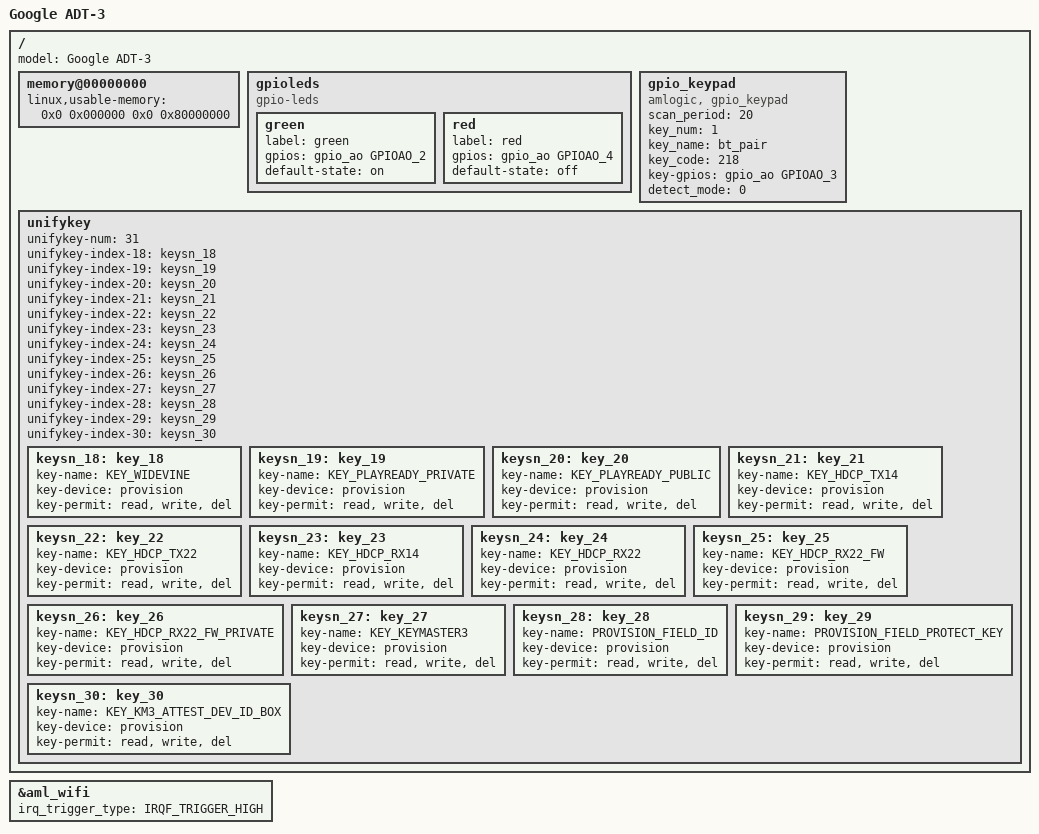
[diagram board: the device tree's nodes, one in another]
// SPDX-License-Identifier: (GPL-2.0+ OR MIT)
/*
 * Google ADT-3 (deadpool), Amlogic S905Y2 (G12A).
 *
 * Shared board description is in g12a_s905y2_common.dtsi.
 */

/dts-v1/;

#include "g12a_s905y2_common.dtsi"

/ {
	model = "Google ADT-3";

	memory@00000000 {
		device_type = "memory";
		linux,usable-memory = <0x0 0x000000 0x0 0x80000000>;
	};

	gpioleds {
		compatible = "gpio-leds";
		status = "okay";

		green {
			label = "green";
			gpios = <&gpio_ao GPIOAO_2 GPIO_ACTIVE_HIGH>;
			default-state = "on";
		};

		red {
			label = "red";
			gpios = <&gpio_ao GPIOAO_4 GPIO_ACTIVE_HIGH>;
			default-state = "off";
		};
	};

	gpio_keypad {
		compatible = "amlogic, gpio_keypad";
		status = "okay";
		scan_period = <20>;
		key_num = <1>;
		key_name = "bt_pair";
		key_code = <218>;
		key-gpios = <&gpio_ao GPIOAO_3 GPIO_ACTIVE_HIGH>;
		detect_mode = <0>;	/* 0:polling, 1:irq */
	};

	/*
	 * Keys 18-30 are the provision-backed DRM, HDCP and keymaster entries.
	 * They are reachable only through a TEE.
	 */
	unifykey {
		unifykey-num = <31>;

		unifykey-index-18= <&keysn_18>;
		unifykey-index-19= <&keysn_19>;
		unifykey-index-20= <&keysn_20>;
		unifykey-index-21= <&keysn_21>;
		unifykey-index-22= <&keysn_22>;
		unifykey-index-23= <&keysn_23>;
		unifykey-index-24= <&keysn_24>;
		unifykey-index-25= <&keysn_25>;
		unifykey-index-26= <&keysn_26>;
		unifykey-index-27= <&keysn_27>;
		unifykey-index-28= <&keysn_28>;
		unifykey-index-29= <&keysn_29>;
		unifykey-index-30= <&keysn_30>;
		keysn_18:key_18 {
			key-name = "KEY_WIDEVINE";
			key-device = "provision";
			key-permit = "read","write","del";
		};
		keysn_19:key_19 {
			key-name = "KEY_PLAYREADY_PRIVATE";
			key-device = "provision";
			key-permit = "read","write","del";
		};
		keysn_20:key_20 {
			key-name = "KEY_PLAYREADY_PUBLIC";
			key-device = "provision";
			key-permit = "read","write","del";
		};
		keysn_21:key_21 {
			key-name = "KEY_HDCP_TX14";
			key-device = "provision";
			key-permit = "read","write","del";
		};
		keysn_22:key_22 {
			key-name = "KEY_HDCP_TX22";
			key-device = "provision";
			key-permit = "read","write","del";
		};
		keysn_23:key_23 {
			key-name = "KEY_HDCP_RX14";
			key-device = "provision";
			key-permit = "read","write","del";
		};
		keysn_24:key_24 {
			key-name = "KEY_HDCP_RX22";
			key-device = "provision";
			key-permit = "read","write","del";
		};
		keysn_25:key_25 {
			key-name = "KEY_HDCP_RX22_FW";
			key-device = "provision";
			key-permit = "read","write","del";
		};
		keysn_26:key_26 {
			key-name = "KEY_HDCP_RX22_FW_PRIVATE";
			key-device = "provision";
			key-permit = "read","write","del";
		};
		keysn_27:key_27 {
			key-name = "KEY_KEYMASTER3";
			key-device = "provision";
			key-permit = "read","write","del";
		};
		keysn_28:key_28 {
			key-name = "PROVISION_FIELD_ID";
			key-device = "provision";
			key-permit = "read","write","del";
		};
		keysn_29:key_29 {
			key-name = "PROVISION_FIELD_PROTECT_KEY";
			key-device = "provision";
			key-permit = "read","write","del";
		};
		keysn_30:key_30 {
			key-name = "KEY_KM3_ATTEST_DEV_ID_BOX";
			key-device = "provision";
			key-permit = "read","write","del";
		};
	};
};

/*
 * AP6356-class BCM4356.
 * The 4.9 board file drove its out-of-band irq active high.
 */
&aml_wifi {
	irq_trigger_type = "IRQF_TRIGGER_HIGH";
};
